# KD32F328CB register map
File version: 1.0
Registers are 32-bit, read-write, reset 0x0 unless marked. A register's access mark holds for its fields unless they carry their own. Offsets are from the block's base; [hi:lo] are bit positions; {n}, {i} and the like mark numbered series.

## ADC — Analog-to-digital converter
Base 0x40012400
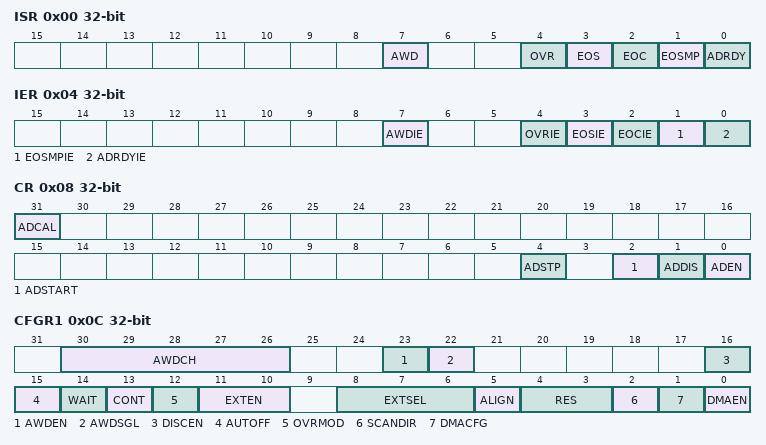
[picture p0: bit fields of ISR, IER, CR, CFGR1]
0x00 ISR — interrupt and status register
  [7] AWD — Analog watchdog flag
  [4] OVR — ADC overrun
  [3] EOS — End of sequence flag
  [2] EOC — End of conversion flag
  [1] EOSMP — End of sampling flag
  [0] ADRDY — ADC ready
0x04 IER — interrupt enable register
  [7] AWDIE — Analog watchdog interrupt enable
  [4] OVRIE — Overrun interrupt enable
  [3] EOSIE — End of conversion sequence interrupt enable
  [2] EOCIE — End of conversion interrupt enable
  [1] EOSMPIE — End of sampling flag interrupt enable
  [0] ADRDYIE — ADC ready interrupt enable
0x08 CR — control register
  [31] ADCAL — ADC calibration
  [4] ADSTP — ADC stop conversion command
  [2] ADSTART — ADC start conversion command
  [1] ADDIS — ADC disable command
  [0] ADEN — ADC enable command
0x0C CFGR1 — configuration register 1
  [30:26] AWDCH — Analog watchdog channel selection
  [23] AWDEN — Analog watchdog enable
  [22] AWDSGL — Enable the watchdog on a single channel or on all channels
  [16] DISCEN — Discontinuous mode
  [15] AUTOFF — Auto-off mode
  [14] WAIT — Wait conversion mode
  [13] CONT — Single / continuous conversion mode
  [12] OVRMOD — Overrun management mode
  [11:10] EXTEN — External trigger enable and polarity selection
  [8:6] EXTSEL — External trigger selection
  [5] ALIGN — Data alignment
  [4:3] RES — Data resolution
  [2] SCANDIR — Scan sequence direction
  [1] DMACFG — Direct memery access configuration
  [0] DMAEN — Direct memory access enable
0x10 CFGR2 reset 0x8000 — configuration register 2
  [31:30] CKMODE — ADC clock mode
0x14 SMPR — sampling time register
  [2:0] SMPR — Sampling time selection
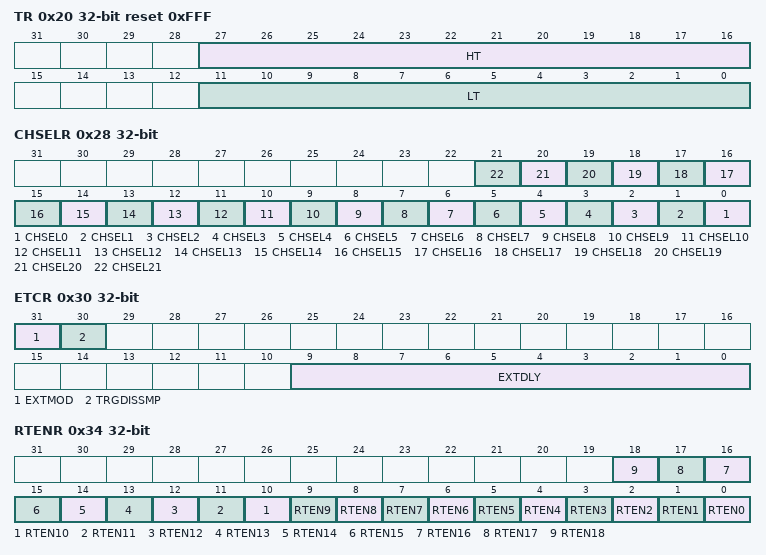
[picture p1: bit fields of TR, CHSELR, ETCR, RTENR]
0x20 TR reset 0xFFF — watchdog threshold register
  [27:16] HT — Analog watchdog higher threshold
  [11:0] LT — Analog watchdog lower threshold
0x28 CHSELR — channel selection register
  [n] CHSEL{n} (n=0..21) — Channel-x selection
0x30 ETCR
  [31] EXTMOD, [30] TRGDISSMP, [9:0] EXTDLY
0x34 RTENR
  [n] RTEN{n} (n=0..18)
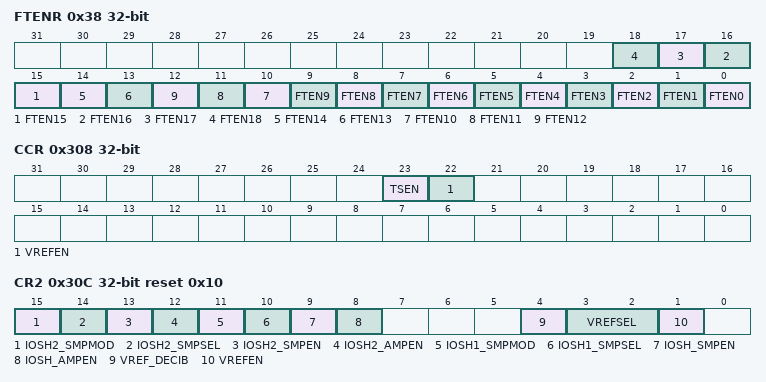
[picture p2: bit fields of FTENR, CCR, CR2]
0x38 FTENR
  [n] FTEN{n} (n=15..18)
  [14] FTEN14 — RTEN14
  [13] FTEN13 — RTEN13
  [n] FTEN{n} (n=0..12)
0x40 DR ro — data register
  [15:0] DATA — Converted data
0x308 CCR — common configuration register
  [23] TSEN — Temperature sensor enable
  [22] VREFEN — Temperature sensor and VREFINT enable
0x30C CR2 reset 0x10 — ADC control register2
  [15] IOSH2_SMPMOD — Sampling circuit enable
  [14] IOSH2_SMPSEL — Sampling circuit enable
  [13] IOSH2_SMPEN — Sampling circuit enable
  [12] IOSH2_AMPEN — Sampling circuit enable
  [11] IOSH1_SMPMOD — Sampling circuit enable
  [10] IOSH1_SMPSEL — Sampling circuit enable
  [9] IOSH_SMPEN — Sampling circuit enable
  [8] IOSH_AMPEN — Sampling circuit keep enable
  [4] VREF_DECIB — Bias circuit half
  [3:2] VREFSEL — Reference voltage select
  [1] VREFEN — Reference voltage enable
0x310 IOSH1DR — common configuration register
  [15:0] IOSH1_DATA — Temperature sensor enable
0x314 IOSH2DR — common configuration register
  [15:0] IOSH2_DATA — Temperature sensor enable

## USART1 — Universal synchronous asynchronous receiver transmitter
Base 0x40013800
Same registers: USART2 0x40004400
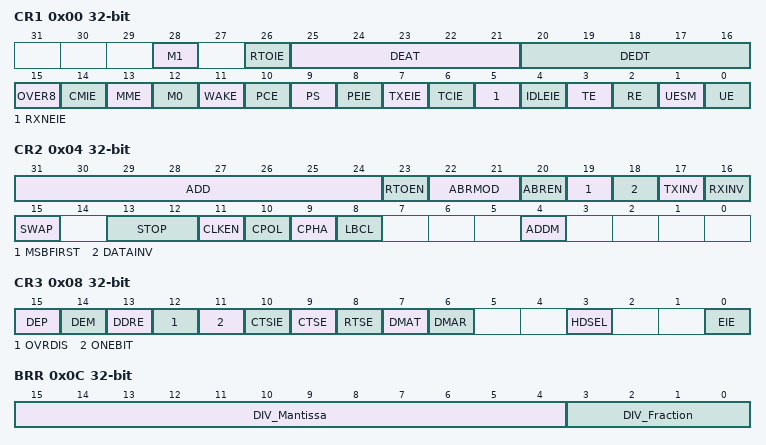
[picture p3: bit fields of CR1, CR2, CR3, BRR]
0x00 CR1 — Control register 1
  [28] M1 — Word length
  [26] RTOIE — Receiver timeout interrupt enable
  [25:21] DEAT — Driver Enable assertion time
  [20:16] DEDT — Driver Enable deassertion time
  [15] OVER8 — Oversampling mode
  [14] CMIE — Character match interrupt enable
  [13] MME — Mute mode enable
  [12] M0 — Word length
  [11] WAKE — Receiver wakeup method
  [10] PCE — Parity control enable
  [9] PS — Parity selection
  [8] PEIE — PE interrupt enable
  [7] TXEIE — interrupt enable
  [6] TCIE — Transmission complete interrupt enable
  [5] RXNEIE — RXNE interrupt enable
  [4] IDLEIE — IDLE interrupt enable
  [3] TE — Transmitter enable
  [2] RE — Receiver enable
  [1] UESM — USART enable in Stop mode
  [0] UE — USART enable
0x04 CR2 — Control register 2
  [31:24] ADD — Address of the USART node
  [23] RTOEN — Receiver timeout enable
  [22:21] ABRMOD — Auto baud rate mode
  [20] ABREN — Auto baud rate enable
  [19] MSBFIRST — Most significant bit first
  [18] DATAINV — Binary data inversion
  [17] TXINV — TX pin active level inversion
  [16] RXINV — RX pin active level inversion
  [15] SWAP — Swap TX/RX pins
  [13:12] STOP — STOP bits
  [11] CLKEN — Clock enable
  [10] CPOL — Clock polarity
  [9] CPHA — Clock phase
  [8] LBCL — Last bit clock pulse
  [4] ADDM — 7-bit Address Detection/4-bit Address Detection
0x08 CR3 — Control register 3
  [15] DEP — Driver enable polarity selection
  [14] DEM — Driver enable mode
  [13] DDRE — DMA Disable on Reception Error
  [12] OVRDIS — Overrun Disable
  [11] ONEBIT — One sample bit method enable
  [10] CTSIE — CTS interrupt enable
  [9] CTSE — CTS enable
  [8] RTSE — RTS enable
  [7] DMAT — DMA enable transmitter
  [6] DMAR — DMA enable receiver
  [3] HDSEL — Half-duplex selection
  [0] EIE — Error interrupt enable
0x0C BRR — Baud rate register
  [15:4] DIV_Mantissa — mantissa of USARTDIV
  [3:0] DIV_Fraction — fraction of USARTDIV
0x14 RTOR — Receiver timeout register
  [23:0] RTO — Receiver timeout value
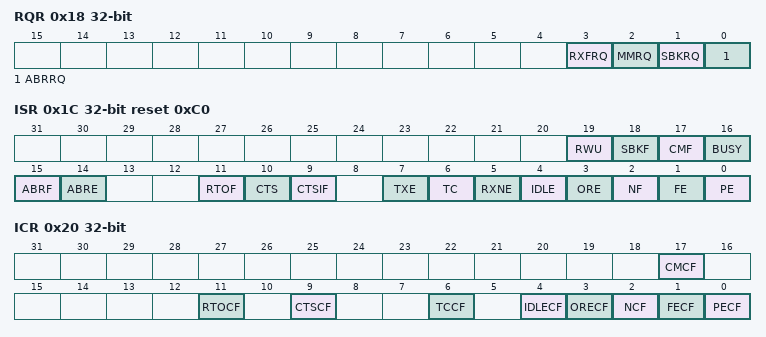
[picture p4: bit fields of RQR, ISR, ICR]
0x18 RQR — Request register
  [3] RXFRQ — Receive data flush request
  [2] MMRQ — Mute mode request
  [1] SBKRQ — Send break request
  [0] ABRRQ — Auto baud rate request
0x1C ISR ro reset 0xC0 — Interrupt & status register
  [19] RWU — Receiver wakeup from Mute mode
  [18] SBKF — Send break flag
  [17] CMF — character match flag
  [16] BUSY — Busy flag
  [15] ABRF — Auto baud rate flag
  [14] ABRE — Auto baud rate error
  [11] RTOF — Receiver timeout
  [10] CTS — CTS flag
  [9] CTSIF — CTS interrupt flag
  [7] TXE — Transmit data register empty
  [6] TC — Transmission complete
  [5] RXNE — Read data register not empty
  [4] IDLE — Idle line detected
  [3] ORE — Overrun error
  [2] NF — Noise detected flag
  [1] FE — Framing error
  [0] PE — Parity error
0x20 ICR — Interrupt flag clear register
  [17] CMCF — Character match clear flag
  [11] RTOCF — Receiver timeout clear flag
  [9] CTSCF — CTS clear flag
  [6] TCCF — Transmission complete clear flag
  [4] IDLECF — Idle line detected clear flag
  [3] ORECF — Overrun error clear flag
  [2] NCF — Noise detected clear flag
  [1] FECF — Framing error clear flag
  [0] PECF — Parity error clear flag
0x24 RDR ro — Receive data register
  [8:0] RDR — Receive data value
0x28 TDR — Transmit data register
  [8:0] TDR — Transmit data value
